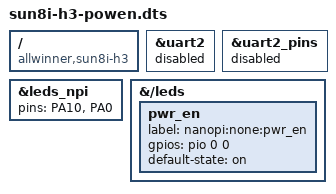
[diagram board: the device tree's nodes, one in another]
// Power up defination
/dts-v1/;
/plugin/;

/ {
    compatible = "allwinner,sun8i-h3";

    fragment@0 {
	target = <&uart2>;
	__overlay__ {
		status = "disabled";
	};
    };

    fragment@1 {
	target = <&uart2_pins>;
	__overlay__ {
		status = "disabled";
	};
    };

    fragment@2 {
	target = <&leds_npi>;
	__overlay__ {
		pins = "PA10", "PA0";
	};
    };

    fragment@3 {
	target-path = "/leds";
	__overlay__ {
		pwr_en {
			label = "nanopi:none:pwr_en";
			gpios = <&pio 0 0 0>;
			default-state = "on";
		};
	};
    };
};
